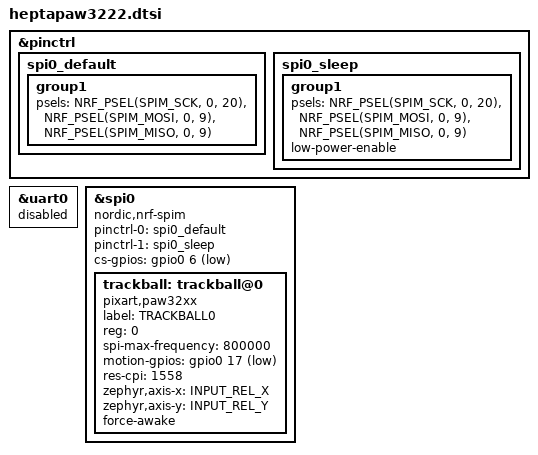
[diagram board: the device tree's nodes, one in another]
/*
 * Copyright (c) 2020 Pete Johanson
 *
 * SPDX-License-Identifier: MIT
 */

#include <zephyr/dt-bindings/input/input-event-codes.h>

&pinctrl {
    spi0_default: spi0_default {
        group1 {
            psels = <NRF_PSEL(SPIM_SCK, 0, 20)>,
                    <NRF_PSEL(SPIM_MOSI, 0, 9)>,
                    <NRF_PSEL(SPIM_MISO, 0, 9)>;
        };
    };

    spi0_sleep: spi0_sleep {
        group1 {
            psels = <NRF_PSEL(SPIM_SCK, 0, 20)>,
                    <NRF_PSEL(SPIM_MOSI, 0, 9)>,
                    <NRF_PSEL(SPIM_MISO, 0, 9)>;
            low-power-enable;
        };
    };
};

&uart0 {
    status = "disabled";
};

&spi0 {
    compatible = "nordic,nrf-spim";
    status = "okay";
    trackball: trackball@0 {
        compatible = "pixart,paw32xx";
        status = "okay";
        label = "TRACKBALL0";
        reg = <0>;
        // spi-max-frequency = <4000000>;
        spi-max-frequency = <800000>;
    };
};

&spi0 {
    pinctrl-0 = <&spi0_default>;
    pinctrl-1 = <&spi0_sleep>;
    pinctrl-names = "default", "sleep";
    cs-gpios = <&gpio0 6 GPIO_ACTIVE_LOW>;
};

&trackball {
  status = "okay";
    motion-gpios = <&gpio0 17 (GPIO_ACTIVE_LOW | GPIO_PULL_UP)>;
    res-cpi = <1558>;
    zephyr,axis-x = <INPUT_REL_X>;
    zephyr,axis-y = <INPUT_REL_Y>;
    force-awake;
};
